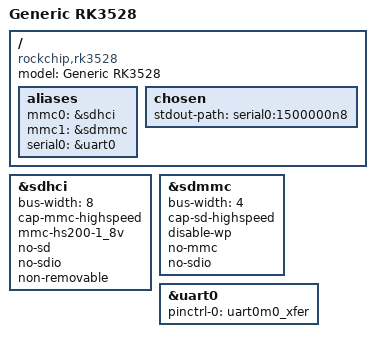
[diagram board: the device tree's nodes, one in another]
// SPDX-License-Identifier: (GPL-2.0+ OR MIT)
/*
 * Minimal generic DT for RK3528 with eMMC and SD-card enabled
 */

/dts-v1/;
#include "rk3528.dtsi"

/ {
	model = "Generic RK3528";
	compatible = "rockchip,rk3528";

	aliases {
		mmc0 = &sdhci;
		mmc1 = &sdmmc;
		serial0 = &uart0;
	};

	chosen {
		stdout-path = "serial0:1500000n8";
	};
};

&sdhci {
	bus-width = <8>;
	cap-mmc-highspeed;
	mmc-hs200-1_8v;
	no-sd;
	no-sdio;
	non-removable;
	status = "okay";
};

&sdmmc {
	bus-width = <4>;
	cap-sd-highspeed;
	disable-wp;
	no-mmc;
	no-sdio;
	status = "okay";
};

&uart0 {
	pinctrl-names = "default";
	pinctrl-0 = <&uart0m0_xfer>;
	status = "okay";
};
